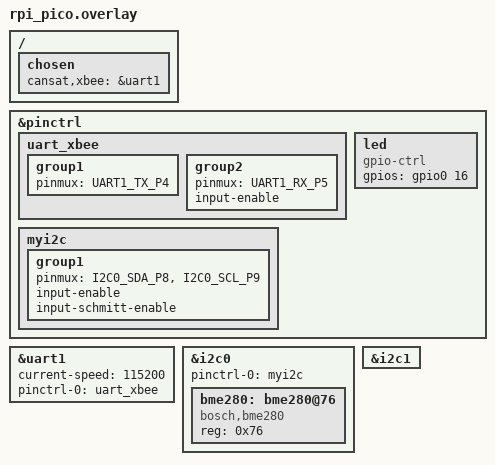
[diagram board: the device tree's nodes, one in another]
/ {
	chosen {
		cansat,xbee = &uart1;
	};
};

&pinctrl{
	uart_xbee: uart_xbee {
		group1 {
			pinmux = <UART1_TX_P4>;
		};
		group2 {
			pinmux = <UART1_RX_P5>;
			input-enable;
		};
	};
	led: led {
        compatible = "gpio-ctrl";
        gpios = <&gpio0 16 0x0>;
    };
};

&uart1 {
	current-speed = <115200>;
	status = "okay";
	pinctrl-0 = <&uart_xbee>;
	pinctrl-names = "default";
};

&pinctrl{
	myi2c: myi2c {
		group1 {
			pinmux = <I2C0_SDA_P8>, <I2C0_SCL_P9>;
			input-enable;
			input-schmitt-enable;
		};
	};
};

&i2c0 {
	status = "okay";
	pinctrl-0 = <&myi2c>;
	// clock-frequency = <I2C_BITRATE_STANDARD>;
	bme280: bme280@76 {
		compatible = "bosch,bme280";
		reg = <0x76>;
	};
};
&i2c1{

};


